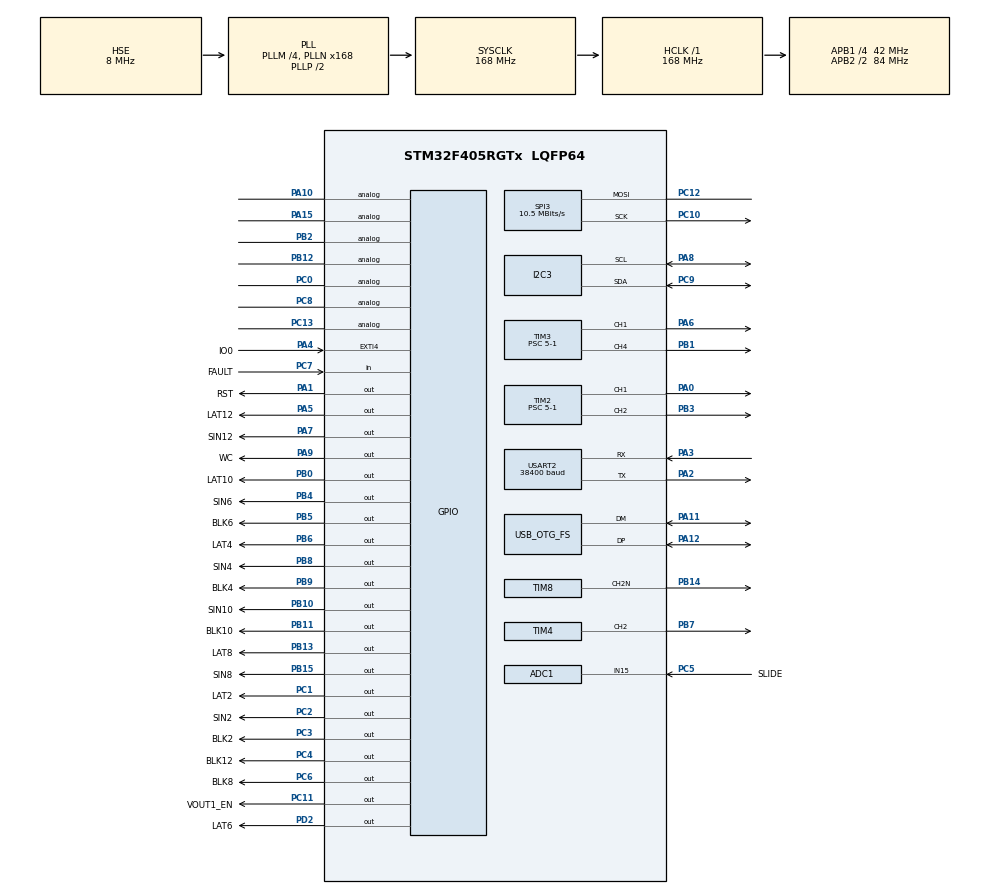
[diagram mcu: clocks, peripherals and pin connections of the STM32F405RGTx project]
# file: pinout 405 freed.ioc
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Dma.SPI3_TX.0.FIFOMode=DMA_FIFOMODE_DISABLE
Dma.SPI3_TX.0.Priority=DMA_PRIORITY_HIGH
FREERTOS.Queues01=myQueue01,2,LEDDataShift_t,0,Dynamic,NULL,NULL
PH0-OSC_IN.Signal=RCC_OSC_IN
SPI3.Direction=SPI_DIRECTION_1LINE
SPI3.VirtualType=VM_MASTER
Dma.USART2_TX.3.MemInc=DMA_MINC_ENABLE
NVIC.DMA1_Stream2_IRQn=true\:5\:0\:false\:false\:true\:true\:false\:true
PC12.Signal=SPI3_MOSI
FREERTOS.Events01=GlobalStatus,Dynamic,NULL
PC6.GPIO_Label=BLK8
VP_RTC_VS_RTC_Activate.Mode=RTC_Enabled
PB6.GPIO_Label=LAT4
PB13.Signal=GPIO_Output
PA5.PinState=GPIO_PIN_RESET
PB3.GPIO_Speed=GPIO_SPEED_FREQ_MEDIUM
TIM3.Channel-PWM\ Generation4\ CH4=TIM_CHANNEL_4
RCC.SYSCLKSource=RCC_SYSCLKSOURCE_PLLCLK
VP_TIM1_VS_no_output1.Mode=PWM Generation1 No Output
VP_TIM2_VS_ClockSourceITR.Mode=TriggerSource_ITR0
TIM8.OCNPolarity_2=TIM_OCNPOLARITY_HIGH
RCC.APB2TimFreq_Value=168000000
PB6.Signal=GPIO_Output
PC7.Signal=GPIO_Input
Dma.ADC1.1.PeriphDataAlignment=DMA_PDATAALIGN_HALFWORD
Dma.USART2_RX.2.Priority=DMA_PRIORITY_HIGH
PC3.Signal=GPIO_Output
PC1.PinState=GPIO_PIN_RESET
Dma.SPI3_TX.0.Direction=DMA_MEMORY_TO_PERIPH
VP_TIM4_VS_ControllerModeTrigger.Mode=Trigger Mode
RCC.RCC_RTC_Clock_Source_FROM_HSE=RCC_RTCCLKSOURCE_HSE_DIV25
PB2.Signal=GPIO_Analog
PC13-ANTI_TAMP.Signal=GPIO_Analog
SH.ADCx_IN15.0=ADC1_IN15,IN15
TIM8.OCMode_PWM-PWM\ Generation2\ CH2N=TIM_OCMODE_PWM1
PC4.GPIO_Label=BLK12
PB1.GPIO_Speed=GPIO_SPEED_FREQ_MEDIUM
PB14.Mode=PWM Generation2 CH2N
RTC.AlarmSubSecondMask=RTC_ALARMSUBSECONDMASK_ALL
PC9.Mode=I2C
SH.S_TIM4_CH2.0=TIM4_CH2,PWM Generation2 CH2
PA8.Signal=I2C3_SCL
TIM4.Period=84-1
VP_TIM1_VS_ClockSourceINT.Mode=Internal
ADC1.SamplingTime-0\#ChannelRegularConversion=ADC_SAMPLETIME_3CYCLES
Mcu.Package=LQFP64
PB9.Signal=GPIO_Output
TIM2.Prescaler=5-1
PB1.Signal=S_TIM3_CH4
NVIC.TimeBase=TIM7_IRQn
SPI3.Mode=SPI_MODE_MASTER
NVIC.TimeBaseIP=TIM7
PA10.Signal=GPIO_Analog
VP_RTC_VS_RTC_Calendar.Mode=RTC_Calendar
Dma.USART2_RX.2.Direction=DMA_PERIPH_TO_MEMORY
TIM2.Pulse-PWM\ Generation2\ CH2=75
RCC.APB2CLKDivider=RCC_HCLK_DIV2
RCC.APB1TimFreq_Value=84000000
TIM1.Period=168-1
PA6.GPIO_Speed=GPIO_SPEED_FREQ_MEDIUM
TIM4.OC2Preload_PWM=DISABLE
NVIC.DMA1_Stream6_IRQn=true\:5\:0\:false\:false\:true\:true\:false\:true
PA4.GPIO_Label=IO0
TIM4.Pulse-PWM\ Generation2\ CH2=75
NVIC.RCC_IRQn=true\:5\:0\:false\:false\:true\:true\:true\:false
NVIC.EXTI4_IRQn=true\:5\:0\:false\:false\:true\:true\:true\:true
NVIC.HASH_RNG_IRQn=true\:5\:0\:false\:false\:true\:true\:true\:true
Dma.I2C3_TX.5.Instance=DMA1_Stream4
FREERTOS.Tasks01=TimerAndLatch,48,128,startTimerAndLatch,Default,NULL,Dynamic,NULL,NULL;LEDShifter,25,128,StartLEDShift,Default,NULL,Dynamic,NULL,NULL;RGBShift,26,512,StartRGBShift,Default,NULL,Dynamic,NULL,NULL;RTCManage,24,256,StartRTCManage,Default,NULL,Dynamic,NULL,NULL;ClockManage,48,512,StartClockMngr,Default,NULL,Dynamic,NULL,NULL
ADC1.Rank-0\#ChannelRegularConversion=1
Dma.I2C3_RX.4.Mode=DMA_NORMAL
PC4.PinState=GPIO_PIN_SET
TIM3.AutoReloadPreload=TIM_AUTORELOAD_PRELOAD_DISABLE
VP_TIM3_VS_ControllerModeTrigger.Mode=Trigger Mode
PA9.GPIO_Label=WC
PC6.Signal=GPIO_Output
PC2.Signal=GPIO_Output
PB11.GPIO_Label=BLK10
VP_TIM8_VS_ClockSourceITR.Mode=TriggerSource_ITR0
Dma.USART2_TX.3.PeriphInc=DMA_PINC_DISABLE
TIM4.TIM_MasterSlaveMode=TIM_MASTERSLAVEMODE_ENABLE
TIM8.TIM_MasterSlaveMode=TIM_MASTERSLAVEMODE_ENABLE
PC0.Signal=GPIO_Analog
RCC.APB1CLKDivider=RCC_HCLK_DIV4
PC14-OSC32_IN.Signal=RCC_OSC32_IN
TIM2.OCPolarity_2=TIM_OCPOLARITY_HIGH
USART2.BaudRate=38400
Dma.USART2_RX.2.Mode=DMA_CIRCULAR
PA0-WKUP.Signal=S_TIM2_CH1_ETR
PA3.Mode=Asynchronous
TIM1.AutoReloadPreload=TIM_AUTORELOAD_PRELOAD_DISABLE
PB8.GPIO_Label=SIN4
TIM3.Pulse-PWM\ Generation1\ CH1=75
Dma.I2C3_RX.4.MemInc=DMA_MINC_ENABLE
RTC.AlarmMaskMinutes=RTC_ALARMMASK_MINUTES
PB14.GPIO_Speed=GPIO_SPEED_FREQ_MEDIUM
Dma.I2C3_RX.4.MemDataAlignment=DMA_MDATAALIGN_BYTE
RTC.Year=21
Dma.I2C3_TX.5.FIFOMode=DMA_FIFOMODE_DISABLE
PA9.Signal=GPIO_Output
PA4.GPIO_ModeDefaultEXTI=GPIO_MODE_IT_RISING_FALLING
VP_TIM8_VS_ClockSourceINT.Mode=Internal
RTC.Format=RTC_FORMAT_BIN
Dma.SPI3_TX.0.PeriphInc=DMA_PINC_DISABLE
Dma.I2C3_TX.5.MemDataAlignment=DMA_MDATAALIGN_BYTE
PB10.Signal=GPIO_Output
PC6.PinState=GPIO_PIN_SET
PB14.Signal=TIM8_CH2N
PA5.Signal=GPIO_Output
PC12.Mode=Simplex_Bidirectional_Master
TIM1.TIM_MasterOutputTrigger=TIM_TRGO_OC1REF
PB13.PinState=GPIO_PIN_RESET
PB4.GPIO_Label=SIN6
PB15.GPIO_Label=SIN8
VP_TIM4_VS_ClockSourceITR.Mode=TriggerSource_ITR0
Dma.USART2_TX.3.Mode=DMA_NORMAL
PA1.GPIO_Label=RST
TIM3.OC4Preload_PWM=DISABLE
Dma.I2C3_TX.5.PeriphInc=DMA_PINC_DISABLE
RCC.RCC_RTC_Clock_SourceVirtual=RCC_RTCCLKSOURCE_HSE_DIV31
Dma.SPI3_TX.0.Instance=DMA1_Stream7
TIM2.Period=84-1
PA13.Mode=Serial_Wire
NVIC.RTC_Alarm_IRQn=true\:5\:0\:false\:false\:true\:true\:true\:true
NVIC.TIM1_BRK_TIM9_IRQn=true\:5\:0\:false\:false\:true\:true\:true\:true
NVIC.TIM1_CC_IRQn=true\:5\:0\:false\:false\:true\:true\:true\:true
TIM8.Period=84-1
PC7.GPIO_Label=FAULT
PA4.Signal=GPXTI4
PB5.Signal=GPIO_Output
ADC1.master=1
PA5.GPIO_Label=LAT12
Dma.SPI3_TX.0.Mode=DMA_NORMAL
PB6.PinState=GPIO_PIN_RESET
PB9.PinState=GPIO_PIN_SET
PA11.Signal=USB_OTG_FS_DM
SH.S_TIM2_CH1_ETR.0=TIM2_CH1,PWM Generation1 CH1
RTC.HourFormat=RTC_HOURFORMAT_12
ProjectManager.HeapSize=0x1000
Dma.I2C3_RX.4.Instance=DMA1_Stream2
Dma.USART2_TX.3.Priority=DMA_PRIORITY_HIGH
VP_TIM4_VS_ClockSourceINT.Mode=Internal
NVIC.PriorityGroup=NVIC_PRIORITYGROUP_4
TIM2.TIM_MasterSlaveMode=TIM_MASTERSLAVEMODE_ENABLE
TIM2.AutoReloadPreload=TIM_AUTORELOAD_PRELOAD_DISABLE
PC3.GPIO_Label=BLK2
PA8.Mode=I2C
PD2.Signal=GPIO_Output
RTC.Seconds=45
PB0.Signal=GPIO_Output
Dma.I2C3_RX.4.FIFOMode=DMA_FIFOMODE_DISABLE
RTC.Date=11
Dma.I2C3_TX.5.Mode=DMA_NORMAL
PC1.Signal=GPIO_Output
PD2.GPIO_Label=LAT6
Mcu.Family=STM32F4
Dma.USART2_RX.2.PeriphDataAlignment=DMA_PDATAALIGN_BYTE
Dma.SPI3_TX.0.MemInc=DMA_MINC_ENABLE
VP_TIM2_VS_OPM.Mode=OPM_bit
USB_DEVICE.CLASS_NAME_FS=CDC
VP_TIM1_VS_OPM.Mode=OPM_bit
RCC.CortexFreq_Value=168000000
Dma.ADC1.1.MemDataAlignment=DMA_MDATAALIGN_HALFWORD
RTC.Alarm=RTC_ALARM_A
TIM1.RepetitionCounter=16-1
VP_TIM3_VS_OPM.Mode=OPM_bit
VP_TIM4_VS_OPM.Mode=OPM_bit
PC10.Signal=SPI3_SCK
PA11.Mode=Device_Only
VP_TIM8_VS_ControllerModeTrigger.Mode=Trigger Mode
PB0.GPIO_Label=LAT10
VP_TIM8_VS_OPM.Mode=OPM_bit
USB_DEVICE.VirtualMode-CDC_FS=Cdc
Dma.USART2_TX.3.Direction=DMA_MEMORY_TO_PERIPH
Dma.SPI3_TX.0.PeriphDataAlignment=DMA_PDATAALIGN_BYTE
TIM2.Channel-PWM\ Generation2\ CH2=TIM_CHANNEL_2
PB13.GPIO_Label=LAT8
PB11.Signal=GPIO_Output
NVIC.DMA1_Stream4_IRQn=true\:5\:0\:false\:false\:true\:true\:false\:true
PB15.Signal=GPIO_Output
VP_RTC_VS_RTC_Alarm_A_Intern.Mode=Alarm A
ProjectManager.StackSize=0x1000
PC3.PinState=GPIO_PIN_SET
VP_FREERTOS_VS_CMSIS_V2.Mode=CMSIS_V2
PA12.Signal=USB_OTG_FS_DP
TIM1.Prescaler=20-1
PB0.PinState=GPIO_PIN_RESET
RCC.RCC_RTC_Clock_Source=RCC_RTCCLKSOURCE_LSE
Dma.ADC1.1.Instance=DMA2_Stream0
RCC.HCLKFreq_Value=168000000
Dma.I2C3_RX.4.Priority=DMA_PRIORITY_LOW
TIM3.Period=84-1
TIM3.OC1Preload_PWM=DISABLE
PB5.PinState=GPIO_PIN_SET
Dma.USART2_RX.2.MemDataAlignment=DMA_MDATAALIGN_BYTE
NVIC.DMA2_Stream0_IRQn=true\:5\:0\:false\:false\:true\:true\:false\:true
RCC.AHBFreq_Value=168000000
PH0-OSC_IN.Mode=HSE-External-Clock-Source
SPI3.DataSize=SPI_DATASIZE_8BIT
TIM3.Channel-PWM\ Generation1\ CH1=TIM_CHANNEL_1
ADC1.Channel-0\#ChannelRegularConversion=ADC_CHANNEL_15
RCC.HSE_VALUE=8000000
RTC.Minutes=10
PA0-WKUP.GPIO_Speed=GPIO_SPEED_FREQ_MEDIUM
Dma.I2C3_TX.5.MemInc=DMA_MINC_ENABLE
RTC.Month=RTC_MONTH_MAY
PC14-OSC32_IN.Mode=LSE-External-Clock-Source
PA14.Mode=Serial_Wire
TIM3.Prescaler=5-1
PC11.GPIO_Label=VOUT1_EN
Dma.ADC1.1.Priority=DMA_PRIORITY_LOW
TIM8.Pulse-PWM\ Generation2\ CH2N=70
PB7.Signal=S_TIM4_CH2
Dma.ADC1.1.Mode=DMA_CIRCULAR
TIM2.Channel-PWM\ Generation1\ CH1=TIM_CHANNEL_1
SH.S_TIM3_CH1.0=TIM3_CH1,PWM Generation1 CH1
VP_TIM3_VS_ClockSourceITR.Mode=TriggerSource_ITR0
TIM8.OC2Preload_PWM=DISABLE
TIM3.OCPolarity_4=TIM_OCPOLARITY_HIGH
Dma.SPI3_TX.0.MemDataAlignment=DMA_MDATAALIGN_BYTE
NVIC.DMA1_Stream7_IRQn=true\:5\:0\:false\:false\:true\:true\:false\:true
TIM3.OCPolarity_1=TIM_OCPOLARITY_HIGH
PH1-OSC_OUT.Mode=HSE-External-Clock-Source
PA6.Signal=S_TIM3_CH1
USART2.VirtualMode=VM_ASYNC
Dma.ADC1.1.Direction=DMA_PERIPH_TO_MEMORY
Dma.I2C3_TX.5.Direction=DMA_MEMORY_TO_PERIPH
NVIC.OTG_FS_IRQn=true\:5\:0\:false\:false\:true\:true\:false\:true
Dma.ADC1.1.MemInc=DMA_MINC_ENABLE
TIM8.Channel-PWM\ Generation2\ CH2N=TIM_CHANNEL_2
USB_OTG_FS.VirtualMode=Device_Only
PA15.Signal=GPIO_Analog
PB11.PinState=GPIO_PIN_SET
TIM8.Prescaler=10-1
PB5.GPIO_Label=BLK6
Dma.Request2=USART2_RX
Dma.Request1=ADC1
Dma.Request4=I2C3_RX
Dma.Request3=USART2_TX
Dma.Request5=I2C3_TX
PC5.Signal=ADCx_IN15
Dma.Request0=SPI3_TX
PC2.GPIO_Label=SIN2
NVIC.TIM7_IRQn=true\:0\:0\:false\:false\:true\:false\:false\:true
VP_TIM3_VS_ClockSourceINT.Mode=Internal
TIM2.OC1Preload_PWM=DISABLE
PB4.Signal=GPIO_Output
PA3.Signal=USART2_RX
PB7.GPIO_Speed=GPIO_SPEED_FREQ_MEDIUM
PC15-OSC32_OUT.Mode=LSE-External-Clock-Source
Dma.USART2_TX.3.MemDataAlignment=DMA_MDATAALIGN_BYTE
PB9.GPIO_Label=BLK4
Dma.USART2_TX.3.Instance=DMA1_Stream6
USB_DEVICE.VirtualModeFS=Cdc_FS
PC4.GPIO_PuPd=GPIO_NOPULL
TIM3.OCMode_PWM-PWM\ Generation4\ CH4=TIM_OCMODE_PWM1
VP_SYS_VS_tim7.Mode=TIM7
PC11.Signal=GPIO_Output
RTC.AlarmMaskDateWeekDay=RTC_ALARMMASK_DATEWEEKDAY
PC8.Signal=GPIO_Analog
PC4.Signal=GPIO_Output
PC10.Mode=Simplex_Bidirectional_Master
TIM1.Pulse-PWM\ Generation1\ No\ Output=150
Dma.I2C3_RX.4.PeriphInc=DMA_PINC_DISABLE
VP_RNG_VS_RNG.Mode=RNG_Activate
TIM2.Pulse-PWM\ Generation1\ CH1=75
TIM1.Channel-PWM\ Generation1\ No\ Output=TIM_CHANNEL_1
PA13.Signal=SYS_JTMS-SWDIO
SH.S_TIM2_CH2.0=TIM2_CH2,PWM Generation2 CH2
NVIC.TIM8_CC_IRQn=true\:5\:0\:false\:false\:true\:true\:true\:true
Dma.USART2_RX.2.MemInc=DMA_MINC_ENABLE
Dma.I2C3_TX.5.PeriphDataAlignment=DMA_PDATAALIGN_BYTE
RTC.TimeFormat=RTC_HOURFORMAT12_AM
ProjectManager.TargetToolchain=STM32CubeIDE
PB10.GPIO_Label=SIN10
NVIC.DMA1_Stream5_IRQn=true\:5\:0\:false\:false\:true\:true\:false\:true
VP_USB_DEVICE_VS_USB_DEVICE_CDC_FS.Mode=CDC_FS
Dma.USART2_TX.3.PeriphDataAlignment=DMA_PDATAALIGN_BYTE
TIM4.Prescaler=5-1
RCC.LSE_VALUE=32768
PC15-OSC32_OUT.Signal=RCC_OSC32_OUT
PA1.Signal=GPIO_Output
Dma.USART2_TX.3.FIFOMode=DMA_FIFOMODE_DISABLE
PD2.PinState=GPIO_PIN_RESET
board=custom
RCC.VCOOutputFreq_Value=336000000
Dma.ADC1.1.FIFOMode=DMA_FIFOMODE_DISABLE
Dma.USART2_RX.2.PeriphInc=DMA_PINC_DISABLE
TIM4.Channel-PWM\ Generation2\ CH2=TIM_CHANNEL_2
RCC.APB2Freq_Value=84000000
SPI3.CalculateBaudRate=10.5 MBits/s
TIM2.OCMode_PWM-PWM\ Generation2\ CH2=TIM_OCMODE_PWM1
VP_TIM2_VS_ClockSourceINT.Mode=Internal
SPI3.BaudRatePrescaler=SPI_BAUDRATEPRESCALER_4
PC1.GPIO_Label=LAT2
PH1-OSC_OUT.Signal=RCC_OSC_OUT
Dma.ADC1.1.PeriphInc=DMA_PINC_DISABLE
Dma.I2C3_RX.4.Direction=DMA_PERIPH_TO_MEMORY
Mcu.Name=STM32F405RGTx
Dma.I2C3_TX.5.Priority=DMA_PRIORITY_LOW
PA2.Signal=USART2_TX
RTC.AlarmMaskHours=RTC_ALARMMASK_HOURS
Dma.I2C3_RX.4.PeriphDataAlignment=DMA_PDATAALIGN_BYTE
RCC.48MHZClocksFreq_Value=48000000
PB3.Signal=S_TIM2_CH2
RCC.SYSCLKFreq_VALUE=168000000
RTC.Hours=12
PA7.GPIO_Label=SIN12
PC2.PinState=GPIO_PIN_RESET
PA12.Mode=Device_Only
VP_TIM2_VS_ControllerModeTrigger.Mode=Trigger Mode
TIM2.OC2Preload_PWM=DISABLE
PC5.GPIO_Label=SLIDE
Dma.USART2_RX.2.Instance=DMA1_Stream5
TIM3.TIM_MasterSlaveMode=TIM_MASTERSLAVEMODE_ENABLE
PA14.Signal=SYS_JTCK-SWCLK
RCC.HSI_VALUE=16000000
RCC.PLLQ=7
ADC1.NbrOfConversionFlag=1
RCC.PLLM=4
RCC.PLLN=168
PA2.Mode=Asynchronous
PB8.Signal=GPIO_Output
Dma.USART2_RX.2.FIFOMode=DMA_FIFOMODE_DISABLE
PC9.Signal=I2C3_SDA
TIM4.OCMode_PWM-PWM\ Generation2\ CH2=TIM_OCMODE_PWM1
RCC.APB1Freq_Value=42000000
TIM3.Pulse-PWM\ Generation4\ CH4=75
PB12.Signal=GPIO_Analog
TIM1.TIM_MasterSlaveMode=TIM_MASTERSLAVEMODE_DISABLE
PC3.GPIO_PuPd=GPIO_NOPULL
SH.S_TIM3_CH4.0=TIM3_CH4,PWM Generation4 CH4
PA7.Signal=GPIO_Output

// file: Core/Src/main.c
/* USER CODE BEGIN Header */
/**
  ******************************************************************************
  * @file           : main.c
  * @brief          : Main program body
  ******************************************************************************
  * @attention
  *
  * <h2><center>&copy; Copyright (c) 2021 STMicroelectronics.
  * All rights reserved.</center></h2>
  *
  * This software component is licensed by ST under Ultimate Liberty license
  * SLA0044, the "License"; You may not use this file except in compliance with
  * the License. You may obtain a copy of the License at:
  *                             www.st.com/SLA0044
  *
  ******************************************************************************
  */
/* USER CODE END Header */
#include "main.h"
#include "cmsis_os.h"
#include "usb_device.h"

/* USER CODE BEGIN Includes */
//#include "time.h"
#include "cheapLibation.h"
#include "ColorDefinitions.h"
#include "mytime.h"
#include "usbd_cdc_if.h"

/* USER CODE END Includes */

/* USER CODE BEGIN PTD */
typedef struct {
	uint8_t flags;
	uint8_t mincnt;
	uint8_t hrcnt;
	uint8_t time;
}LEDDataShift_t;

/* USER CODE END PTD */

/* USER CODE BEGIN PD */
#define NUMLED 60
#define GLOBAL 0
#define R_LED 3
#define B_LED 1
#define G_LED 2
#define MINMASK 0x00000001U
#define HRMASK	0x00000002U
#define LATMASK	0x00000008U
#define TIMMASK	0x00000004U
#define WIFISTATUS 0x000080U
#define WIFISTATUSD 0x000100U
#define ESPDATA 0x000040U
#define SETTIME 0x000020U

/* USER CODE END PD */

ADC_HandleTypeDef hadc1;
DMA_HandleTypeDef hdma_adc1;

I2C_HandleTypeDef hi2c3;
DMA_HandleTypeDef hdma_i2c3_rx;
DMA_HandleTypeDef hdma_i2c3_tx;

RNG_HandleTypeDef hrng;

RTC_HandleTypeDef hrtc;

SPI_HandleTypeDef hspi3;
DMA_HandleTypeDef hdma_spi3_tx;

TIM_HandleTypeDef htim1;
TIM_HandleTypeDef htim2;
TIM_HandleTypeDef htim3;
TIM_HandleTypeDef htim4;
TIM_HandleTypeDef htim8;

UART_HandleTypeDef huart2;
DMA_HandleTypeDef hdma_usart2_rx;
DMA_HandleTypeDef hdma_usart2_tx;

/* Definitions for TimerAndLatch */
osThreadId_t TimerAndLatchHandle;
const osThreadAttr_t TimerAndLatch_attributes = {
  .name = "TimerAndLatch",
  .stack_size = 128 * 4,
  .priority = (osPriority_t) osPriorityRealtime,
};
/* Definitions for LEDShifter */
osThreadId_t LEDShifterHandle;
const osThreadAttr_t LEDShifter_attributes = {
  .name = "LEDShifter",
  .stack_size = 128 * 4,
  .priority = (osPriority_t) osPriorityNormal1,
};
/* Definitions for RGBShift */
osThreadId_t RGBShiftHandle;
const osThreadAttr_t RGBShift_attributes = {
  .name = "RGBShift",
  .stack_size = 512 * 4,
  .priority = (osPriority_t) osPriorityNormal2,
};
/* Definitions for RTCManage */
osThreadId_t RTCManageHandle;
const osThreadAttr_t RTCManage_attributes = {
  .name = "RTCManage",
  .stack_size = 256 * 4,
  .priority = (osPriority_t) osPriorityNormal,
};
/* Definitions for ClockManage */
osThreadId_t ClockManageHandle;
const osThreadAttr_t ClockManage_attributes = {
  .name = "ClockManage",
  .stack_size = 512 * 4,
  .priority = (osPriority_t) osPriorityRealtime,
};
/* Definitions for myQueue01 */
osMessageQueueId_t myQueue01Handle;
const osMessageQueueAttr_t myQueue01_attributes = {
  .name = "myQueue01"
};
/* Definitions for GlobalStatus */
osEventFlagsId_t GlobalStatusHandle;
const osEventFlagsAttr_t GlobalStatus_attributes = {
  .name = "GlobalStatus"
};
/* USER CODE BEGIN PV */
uint32_t data[] = {0x70007000, 0x00, 0x08080000};
uint16_t newarr[6];
//DMA_HandleTypeDef hdma_memtomem_dma1_channel1;

uint8_t rxbuff[] = {0x00, 0x00, 0x00, 0x00, 0x00, 0x00, 0x00, 0x00 };
uint8_t txbuff[] = {0x55, 0x00, 0x00, 0x00, 0x00, 0x00, 0x00, 0x00 , 0x00, 0x00 };
uint8_t wififlag = 0;
uint8_t hrs = 0x00;
uint8_t min = 0x00;
/* USER CODE END PV */

void SystemClock_Config(void);
static void MX_GPIO_Init(void);
static void MX_DMA_Init(void);
static void MX_TIM3_Init(void);
static void MX_TIM2_Init(void);
static void MX_TIM1_Init(void);
static void MX_TIM8_Init(void);
static void MX_TIM4_Init(void);
static void MX_SPI3_Init(void);
static void MX_ADC1_Init(void);
static void MX_I2C3_Init(void);
static void MX_USART2_UART_Init(void);
static void MX_RTC_Init(void);
static void MX_RNG_Init(void);
void startTimerAndLatch(void *argument);
void StartLEDShift(void *argument);
void StartRGBShift(void *argument);
void StartRTCManage(void *argument);
void StartClockMngr(void *argument);

/* USER CODE BEGIN PFP */

void HAL_TIM_PWM_PulseFinishedCallback(TIM_HandleTypeDef *htim);
void HAL_GPIO_EXTI_Callback(uint16_t GPIO_Pin);
void HAL_RTC_AlarmAEventCallback(RTC_HandleTypeDef *hrtc);

/* USER CODE END PFP */

int main(void)
{

  /* MCU Configuration--------------------------------------------------------*/

  /* Reset of all peripherals, Initializes the Flash interface and the Systick. */
  HAL_Init();

  /* Configure the system clock */
  SystemClock_Config();

  /* Initialize all configured peripherals */
  MX_GPIO_Init();
  MX_DMA_Init();
  MX_TIM3_Init();
  MX_TIM2_Init();
  MX_TIM1_Init();
  MX_TIM8_Init();
  MX_TIM4_Init();
  MX_SPI3_Init();
  MX_ADC1_Init();
  MX_I2C3_Init();
  MX_USART2_UART_Init();
  MX_RTC_Init();
  MX_RNG_Init();
  /* USER CODE BEGIN 2 */

  // reset wifi to programming mode
//  HAL_GPIO_WritePin(IO0_GPIO_Port, IO0_Pin, GPIO_PIN_SET);
  HAL_GPIO_WritePin(RST_GPIO_Port, RST_Pin, GPIO_PIN_RESET);
//  HAL_Delay(500);
//  HAL_GPIO_WritePin(RST_GPIO_Port, RST_Pin, GPIO_PIN_SET);

  // enable all the slave timers
  HAL_TIM_PWM_Start(&htim2, TIM_CHANNEL_2);
  HAL_TIM_PWM_Start(&htim2, TIM_CHANNEL_1);
  HAL_TIM_PWM_Start(&htim3, TIM_CHANNEL_1);
  HAL_TIM_PWM_Start(&htim3, TIM_CHANNEL_4);
  HAL_TIM_PWM_Start(&htim4, TIM_CHANNEL_2);
  HAL_TIMEx_PWMN_Start(&htim8, TIM_CHANNEL_2);
//  uint8_t sttest = beatsin8()

//  time_t now;
//  localtime_r(&now);
//  setenv("TZ")

  /* USER CODE END 2 */

  /* Init scheduler */
  osKernelInitialize();

  /* Create the queue(s) */
  /* creation of myQueue01 */
  myQueue01Handle = osMessageQueueNew (2, sizeof(LEDDataShift_t), &myQueue01_attributes);

  /* Create the thread(s) */
  /* creation of TimerAndLatch */
  TimerAndLatchHandle = osThreadNew(startTimerAndLatch, NULL, &TimerAndLatch_attributes);

  /* creation of LEDShifter */
  LEDShifterHandle = osThreadNew(StartLEDShift, NULL, &LEDShifter_attributes);

  /* creation of RGBShift */
  RGBShiftHandle = osThreadNew(StartRGBShift, NULL, &RGBShift_attributes);

  /* creation of RTCManage */
  RTCManageHandle = osThreadNew(StartRTCManage, NULL, &RTCManage_attributes);

  /* creation of ClockManage */
  ClockManageHandle = osThreadNew(StartClockMngr, NULL, &ClockManage_attributes);

  /* Create the event(s) */
  /* creation of GlobalStatus */
  GlobalStatusHandle = osEventFlagsNew(&GlobalStatus_attributes);

  /* Start scheduler */
  osKernelStart();

  /* We should never get here as control is now taken by the scheduler */
  /* Infinite loop */
  while (1)
  {

  }
}

void SystemClock_Config(void)
{
  RCC_OscInitTypeDef RCC_OscInitStruct = {0};
  RCC_ClkInitTypeDef RCC_ClkInitStruct = {0};
  RCC_PeriphCLKInitTypeDef PeriphClkInitStruct = {0};

  /** Configure the main internal regulator output voltage
  */
  __HAL_RCC_PWR_CLK_ENABLE();
  __HAL_PWR_VOLTAGESCALING_CONFIG(PWR_REGULATOR_VOLTAGE_SCALE1);
  /** Initializes the RCC Oscillators according to the specified parameters
  * in the RCC_OscInitTypeDef structure.
  */
  RCC_OscInitStruct.OscillatorType = RCC_OSCILLATORTYPE_HSE|RCC_OSCILLATORTYPE_LSE;
  RCC_OscInitStruct.HSEState = RCC_HSE_BYPASS;
  RCC_OscInitStruct.LSEState = RCC_LSE_BYPASS;
  RCC_OscInitStruct.PLL.PLLState = RCC_PLL_ON;
  RCC_OscInitStruct.PLL.PLLSource = RCC_PLLSOURCE_HSE;
  RCC_OscInitStruct.PLL.PLLM = 4;
  RCC_OscInitStruct.PLL.PLLN = 168;
  RCC_OscInitStruct.PLL.PLLP = RCC_PLLP_DIV2;
  RCC_OscInitStruct.PLL.PLLQ = 7;
  if (HAL_RCC_OscConfig(&RCC_OscInitStruct) != HAL_OK)
  {
    Error_Handler();
  }
  /** Initializes the CPU, AHB and APB buses clocks
  */
  RCC_ClkInitStruct.ClockType = RCC_CLOCKTYPE_HCLK|RCC_CLOCKTYPE_SYSCLK
                              |RCC_CLOCKTYPE_PCLK1|RCC_CLOCKTYPE_PCLK2;
  RCC_ClkInitStruct.SYSCLKSource = RCC_SYSCLKSOURCE_PLLCLK;
  RCC_ClkInitStruct.AHBCLKDivider = RCC_SYSCLK_DIV1;
  RCC_ClkInitStruct.APB1CLKDivider = RCC_HCLK_DIV4;
  RCC_ClkInitStruct.APB2CLKDivider = RCC_HCLK_DIV2;

  if (HAL_RCC_ClockConfig(&RCC_ClkInitStruct, FLASH_LATENCY_5) != HAL_OK)
  {
    Error_Handler();
  }
  PeriphClkInitStruct.PeriphClockSelection = RCC_PERIPHCLK_RTC;
  PeriphClkInitStruct.RTCClockSelection = RCC_RTCCLKSOURCE_LSE;
  if (HAL_RCCEx_PeriphCLKConfig(&PeriphClkInitStruct) != HAL_OK)
  {
    Error_Handler();
  }
}

static void MX_ADC1_Init(void)
{

  ADC_ChannelConfTypeDef sConfig = {0};

  /** Configure the global features of the ADC (Clock, Resolution, Data Alignment and number of conversion)
  */
  hadc1.Instance = ADC1;
  hadc1.Init.ClockPrescaler = ADC_CLOCK_SYNC_PCLK_DIV4;
  hadc1.Init.Resolution = ADC_RESOLUTION_12B;
  hadc1.Init.ScanConvMode = DISABLE;
  hadc1.Init.ContinuousConvMode = DISABLE;
  hadc1.Init.DiscontinuousConvMode = DISABLE;
  hadc1.Init.ExternalTrigConvEdge = ADC_EXTERNALTRIGCONVEDGE_NONE;
  hadc1.Init.ExternalTrigConv = ADC_SOFTWARE_START;
  hadc1.Init.DataAlign = ADC_DATAALIGN_RIGHT;
  hadc1.Init.NbrOfConversion = 1;
  hadc1.Init.DMAContinuousRequests = DISABLE;
  hadc1.Init.EOCSelection = ADC_EOC_SINGLE_CONV;
  if (HAL_ADC_Init(&hadc1) != HAL_OK)
  {
    Error_Handler();
  }
  /** Configure for the selected ADC regular channel its corresponding rank in the sequencer and its sample time.
  */
  sConfig.Channel = ADC_CHANNEL_15;
  sConfig.Rank = 1;
  sConfig.SamplingTime = ADC_SAMPLETIME_3CYCLES;
  if (HAL_ADC_ConfigChannel(&hadc1, &sConfig) != HAL_OK)
  {
    Error_Handler();
  }

}

static void MX_I2C3_Init(void)
{

  hi2c3.Instance = I2C3;
  hi2c3.Init.ClockSpeed = 100000;
  hi2c3.Init.DutyCycle = I2C_DUTYCYCLE_2;
  hi2c3.Init.OwnAddress1 = 0;
  hi2c3.Init.AddressingMode = I2C_ADDRESSINGMODE_7BIT;
  hi2c3.Init.DualAddressMode = I2C_DUALADDRESS_DISABLE;
  hi2c3.Init.OwnAddress2 = 0;
  hi2c3.Init.GeneralCallMode = I2C_GENERALCALL_DISABLE;
  hi2c3.Init.NoStretchMode = I2C_NOSTRETCH_DISABLE;
  if (HAL_I2C_Init(&hi2c3) != HAL_OK)
  {
    Error_Handler();
  }

}

static void MX_RNG_Init(void)
{

  hrng.Instance = RNG;
  if (HAL_RNG_Init(&hrng) != HAL_OK)
  {
    Error_Handler();
  }

}

static void MX_RTC_Init(void)
{

  RTC_TimeTypeDef sTime = {0};
  RTC_DateTypeDef sDate = {0};
  RTC_AlarmTypeDef sAlarm = {0};

  /** Initialize RTC Only
  */
  hrtc.Instance = RTC;
  hrtc.Init.HourFormat = RTC_HOURFORMAT_12;
  hrtc.Init.AsynchPrediv = 127;
  hrtc.Init.SynchPrediv = 255;
  hrtc.Init.OutPut = RTC_OUTPUT_DISABLE;
  hrtc.Init.OutPutPolarity = RTC_OUTPUT_POLARITY_HIGH;
  hrtc.Init.OutPutType = RTC_OUTPUT_TYPE_OPENDRAIN;
  if (HAL_RTC_Init(&hrtc) != HAL_OK)
  {
    Error_Handler();
  }

  /** Initialize RTC and set the Time and Date
  */
  sTime.Hours = 12;
  sTime.Minutes = 10;
  sTime.Seconds = 45;
  sTime.TimeFormat = RTC_HOURFORMAT12_AM;
  sTime.DayLightSaving = RTC_DAYLIGHTSAVING_NONE;
  sTime.StoreOperation = RTC_STOREOPERATION_RESET;
  if (HAL_RTC_SetTime(&hrtc, &sTime, RTC_FORMAT_BIN) != HAL_OK)
  {
    Error_Handler();
  }
  sDate.WeekDay = RTC_WEEKDAY_MONDAY;
  sDate.Month = RTC_MONTH_MAY;
  sDate.Date = 11;
  sDate.Year = 21;

  if (HAL_RTC_SetDate(&hrtc, &sDate, RTC_FORMAT_BIN) != HAL_OK)
  {
    Error_Handler();
  }
  /** Enable the Alarm A
  */
  sAlarm.AlarmTime.Hours = 1;
  sAlarm.AlarmTime.Minutes = 0;
  sAlarm.AlarmTime.Seconds = 0;
  sAlarm.AlarmTime.SubSeconds = 0;
  sAlarm.AlarmTime.TimeFormat = RTC_HOURFORMAT12_AM;
  sAlarm.AlarmTime.DayLightSaving = RTC_DAYLIGHTSAVING_NONE;
  sAlarm.AlarmTime.StoreOperation = RTC_STOREOPERATION_RESET;
  sAlarm.AlarmMask = RTC_ALARMMASK_DATEWEEKDAY|RTC_ALARMMASK_HOURS
                              |RTC_ALARMMASK_MINUTES;
  sAlarm.AlarmSubSecondMask = RTC_ALARMSUBSECONDMASK_ALL;
  sAlarm.AlarmDateWeekDaySel = RTC_ALARMDATEWEEKDAYSEL_DATE;
  sAlarm.AlarmDateWeekDay = 1;
  sAlarm.Alarm = RTC_ALARM_A;
  if (HAL_RTC_SetAlarm_IT(&hrtc, &sAlarm, RTC_FORMAT_BIN) != HAL_OK)
  {
    Error_Handler();
  }

}

static void MX_SPI3_Init(void)
{

  /* SPI3 parameter configuration*/
  hspi3.Instance = SPI3;
  hspi3.Init.Mode = SPI_MODE_MASTER;
  hspi3.Init.Direction = SPI_DIRECTION_1LINE;
  hspi3.Init.DataSize = SPI_DATASIZE_8BIT;
  hspi3.Init.CLKPolarity = SPI_POLARITY_LOW;
  hspi3.Init.CLKPhase = SPI_PHASE_1EDGE;
  hspi3.Init.NSS = SPI_NSS_SOFT;
  hspi3.Init.BaudRatePrescaler = SPI_BAUDRATEPRESCALER_4;
  hspi3.Init.FirstBit = SPI_FIRSTBIT_MSB;
  hspi3.Init.TIMode = SPI_TIMODE_DISABLE;
  hspi3.Init.CRCCalculation = SPI_CRCCALCULATION_DISABLE;
  hspi3.Init.CRCPolynomial = 10;
  if (HAL_SPI_Init(&hspi3) != HAL_OK)
  {
    Error_Handler();
  }

}

static void MX_TIM1_Init(void)
{

  TIM_ClockConfigTypeDef sClockSourceConfig = {0};
  TIM_MasterConfigTypeDef sMasterConfig = {0};
  TIM_OC_InitTypeDef sConfigOC = {0};
  TIM_BreakDeadTimeConfigTypeDef sBreakDeadTimeConfig = {0};

  htim1.Instance = TIM1;
  htim1.Init.Prescaler = 20-1;
  htim1.Init.CounterMode = TIM_COUNTERMODE_UP;
  htim1.Init.Period = 168-1;
  htim1.Init.ClockDivision = TIM_CLOCKDIVISION_DIV1;
  htim1.Init.RepetitionCounter = 16-1;
  htim1.Init.AutoReloadPreload = TIM_AUTORELOAD_PRELOAD_DISABLE;
  if (HAL_TIM_Base_Init(&htim1) != HAL_OK)
  {
    Error_Handler();
  }
  sClockSourceConfig.ClockSource = TIM_CLOCKSOURCE_INTERNAL;
  if (HAL_TIM_ConfigClockSource(&htim1, &sClockSourceConfig) != HAL_OK)
  {
    Error_Handler();
  }
  if (HAL_TIM_PWM_Init(&htim1) != HAL_OK)
  {
    Error_Handler();
  }
  if (HAL_TIM_OnePulse_Init(&htim1, TIM_OPMODE_SINGLE) != HAL_OK)
  {
    Error_Handler();
  }
  sMasterConfig.MasterOutputTrigger = TIM_TRGO_OC1REF;
  sMasterConfig.MasterSlaveMode = TIM_MASTERSLAVEMODE_DISABLE;
  if (HAL_TIMEx_MasterConfigSynchronization(&htim1, &sMasterConfig) != HAL_OK)
  {
    Error_Handler();
  }
  sConfigOC.OCMode = TIM_OCMODE_PWM1;
  sConfigOC.Pulse = 150;
  sConfigOC.OCPolarity = TIM_OCPOLARITY_HIGH;
  sConfigOC.OCNPolarity = TIM_OCNPOLARITY_HIGH;
  sConfigOC.OCFastMode = TIM_OCFAST_DISABLE;
  sConfigOC.OCIdleState = TIM_OCIDLESTATE_RESET;
  sConfigOC.OCNIdleState = TIM_OCNIDLESTATE_RESET;
  if (HAL_TIM_PWM_ConfigChannel(&htim1, &sConfigOC, TIM_CHANNEL_1) != HAL_OK)
  {
    Error_Handler();
  }
  sBreakDeadTimeConfig.OffStateRunMode = TIM_OSSR_DISABLE;
  sBreakDeadTimeConfig.OffStateIDLEMode = TIM_OSSI_DISABLE;
  sBreakDeadTimeConfig.LockLevel = TIM_LOCKLEVEL_OFF;
  sBreakDeadTimeConfig.DeadTime = 0;
  sBreakDeadTimeConfig.BreakState = TIM_BREAK_DISABLE;
  sBreakDeadTimeConfig.BreakPolarity = TIM_BREAKPOLARITY_HIGH;
  sBreakDeadTimeConfig.AutomaticOutput = TIM_AUTOMATICOUTPUT_DISABLE;
  if (HAL_TIMEx_ConfigBreakDeadTime(&htim1, &sBreakDeadTimeConfig) != HAL_OK)
  {
    Error_Handler();
  }

}

static void MX_TIM2_Init(void)
{

  TIM_ClockConfigTypeDef sClockSourceConfig = {0};
  TIM_SlaveConfigTypeDef sSlaveConfig = {0};
  TIM_MasterConfigTypeDef sMasterConfig = {0};
  TIM_OC_InitTypeDef sConfigOC = {0};

  htim2.Instance = TIM2;
  htim2.Init.Prescaler = 5-1;
  htim2.Init.CounterMode = TIM_COUNTERMODE_UP;
  htim2.Init.Period = 84-1;
  htim2.Init.ClockDivision = TIM_CLOCKDIVISION_DIV1;
  htim2.Init.AutoReloadPreload = TIM_AUTORELOAD_PRELOAD_DISABLE;
  if (HAL_TIM_Base_Init(&htim2) != HAL_OK)
  {
    Error_Handler();
  }
  sClockSourceConfig.ClockSource = TIM_CLOCKSOURCE_INTERNAL;
  if (HAL_TIM_ConfigClockSource(&htim2, &sClockSourceConfig) != HAL_OK)
  {
    Error_Handler();
  }
  if (HAL_TIM_PWM_Init(&htim2) != HAL_OK)
  {
    Error_Handler();
  }
  if (HAL_TIM_OnePulse_Init(&htim2, TIM_OPMODE_SINGLE) != HAL_OK)
  {
    Error_Handler();
  }
  sSlaveConfig.SlaveMode = TIM_SLAVEMODE_TRIGGER;
  sSlaveConfig.InputTrigger = TIM_TS_ITR0;
  if (HAL_TIM_SlaveConfigSynchro(&htim2, &sSlaveConfig) != HAL_OK)
  {
    Error_Handler();
  }
  sMasterConfig.MasterOutputTrigger = TIM_TRGO_RESET;
  sMasterConfig.MasterSlaveMode = TIM_MASTERSLAVEMODE_ENABLE;
  if (HAL_TIMEx_MasterConfigSynchronization(&htim2, &sMasterConfig) != HAL_OK)
  {
    Error_Handler();
  }
  sConfigOC.OCMode = TIM_OCMODE_PWM1;
  sConfigOC.Pulse = 75;
  sConfigOC.OCPolarity = TIM_OCPOLARITY_HIGH;
  sConfigOC.OCFastMode = TIM_OCFAST_DISABLE;
  if (HAL_TIM_PWM_ConfigChannel(&htim2, &sConfigOC, TIM_CHANNEL_1) != HAL_OK)
  {
    Error_Handler();
  }
  __HAL_TIM_DISABLE_OCxPRELOAD(&htim2, TIM_CHANNEL_1);
  if (HAL_TIM_PWM_ConfigChannel(&htim2, &sConfigOC, TIM_CHANNEL_2) != HAL_OK)
  {
    Error_Handler();
  }
  __HAL_TIM_DISABLE_OCxPRELOAD(&htim2, TIM_CHANNEL_2);
  HAL_TIM_MspPostInit(&htim2);

}

static void MX_TIM3_Init(void)
{

  TIM_ClockConfigTypeDef sClockSourceConfig = {0};
  TIM_SlaveConfigTypeDef sSlaveConfig = {0};
  TIM_MasterConfigTypeDef sMasterConfig = {0};
  TIM_OC_InitTypeDef sConfigOC = {0};

  htim3.Instance = TIM3;
  htim3.Init.Prescaler = 5-1;
  htim3.Init.CounterMode = TIM_COUNTERMODE_UP;
  htim3.Init.Period = 84-1;
  htim3.Init.ClockDivision = TIM_CLOCKDIVISION_DIV1;
  htim3.Init.AutoReloadPreload = TIM_AUTORELOAD_PRELOAD_DISABLE;
  if (HAL_TIM_Base_Init(&htim3) != HAL_OK)
  {
    Error_Handler();
  }
  sClockSourceConfig.ClockSource = TIM_CLOCKSOURCE_INTERNAL;
  if (HAL_TIM_ConfigClockSource(&htim3, &sClockSourceConfig) != HAL_OK)
  {
    Error_Handler();
  }
  if (HAL_TIM_PWM_Init(&htim3) != HAL_OK)
  {
    Error_Handler();
  }
  if (HAL_TIM_OnePulse_Init(&htim3, TIM_OPMODE_SINGLE) != HAL_OK)
  {
    Error_Handler();
  }
  sSlaveConfig.SlaveMode = TIM_SLAVEMODE_TRIGGER;
  sSlaveConfig.InputTrigger = TIM_TS_ITR0;
  if (HAL_TIM_SlaveConfigSynchro(&htim3, &sSlaveConfig) != HAL_OK)
  {
    Error_Handler();
  }
  sMasterConfig.MasterOutputTrigger = TIM_TRGO_RESET;
  sMasterConfig.MasterSlaveMode = TIM_MASTERSLAVEMODE_ENABLE;
  if (HAL_TIMEx_MasterConfigSynchronization(&htim3, &sMasterConfig) != HAL_OK)
  {
    Error_Handler();
  }
  sConfigOC.OCMode = TIM_OCMODE_PWM1;
  sConfigOC.Pulse = 75;
  sConfigOC.OCPolarity = TIM_OCPOLARITY_HIGH;
  sConfigOC.OCFastMode = TIM_OCFAST_DISABLE;
  if (HAL_TIM_PWM_ConfigChannel(&htim3, &sConfigOC, TIM_CHANNEL_1) != HAL_OK)
  {
    Error_Handler();
  }
  __HAL_TIM_DISABLE_OCxPRELOAD(&htim3, TIM_CHANNEL_1);
  if (HAL_TIM_PWM_ConfigChannel(&htim3, &sConfigOC, TIM_CHANNEL_4) != HAL_OK)
  {
    Error_Handler();
  }
  __HAL_TIM_DISABLE_OCxPRELOAD(&htim3, TIM_CHANNEL_4);
  HAL_TIM_MspPostInit(&htim3);

}

static void MX_TIM4_Init(void)
{

  TIM_ClockConfigTypeDef sClockSourceConfig = {0};
  TIM_SlaveConfigTypeDef sSlaveConfig = {0};
  TIM_MasterConfigTypeDef sMasterConfig = {0};
  TIM_OC_InitTypeDef sConfigOC = {0};

  htim4.Instance = TIM4;
  htim4.Init.Prescaler = 5-1;
  htim4.Init.CounterMode = TIM_COUNTERMODE_UP;
  htim4.Init.Period = 84-1;
  htim4.Init.ClockDivision = TIM_CLOCKDIVISION_DIV1;
  htim4.Init.AutoReloadPreload = TIM_AUTORELOAD_PRELOAD_DISABLE;
  if (HAL_TIM_Base_Init(&htim4) != HAL_OK)
  {
    Error_Handler();
  }
  sClockSourceConfig.ClockSource = TIM_CLOCKSOURCE_INTERNAL;
  if (HAL_TIM_ConfigClockSource(&htim4, &sClockSourceConfig) != HAL_OK)
  {
    Error_Handler();
  }
  if (HAL_TIM_PWM_Init(&htim4) != HAL_OK)
  {
    Error_Handler();
  }
  if (HAL_TIM_OnePulse_Init(&htim4, TIM_OPMODE_SINGLE) != HAL_OK)
  {
    Error_Handler();
  }
  sSlaveConfig.SlaveMode = TIM_SLAVEMODE_TRIGGER;
  sSlaveConfig.InputTrigger = TIM_TS_ITR0;
  if (HAL_TIM_SlaveConfigSynchro(&htim4, &sSlaveConfig) != HAL_OK)
  {
    Error_Handler();
  }
  sMasterConfig.MasterOutputTrigger = TIM_TRGO_RESET;
  sMasterConfig.MasterSlaveMode = TIM_MASTERSLAVEMODE_ENABLE;
  if (HAL_TIMEx_MasterConfigSynchronization(&htim4, &sMasterConfig) != HAL_OK)
  {
    Error_Handler();
  }
  sConfigOC.OCMode = TIM_OCMODE_PWM1;
  sConfigOC.Pulse = 75;
  sConfigOC.OCPolarity = TIM_OCPOLARITY_HIGH;
  sConfigOC.OCFastMode = TIM_OCFAST_DISABLE;
  if (HAL_TIM_PWM_ConfigChannel(&htim4, &sConfigOC, TIM_CHANNEL_2) != HAL_OK)
  {
    Error_Handler();
  }
  __HAL_TIM_DISABLE_OCxPRELOAD(&htim4, TIM_CHANNEL_2);
  HAL_TIM_MspPostInit(&htim4);

}

static void MX_TIM8_Init(void)
{

  TIM_ClockConfigTypeDef sClockSourceConfig = {0};
  TIM_SlaveConfigTypeDef sSlaveConfig = {0};
  TIM_MasterConfigTypeDef sMasterConfig = {0};
  TIM_OC_InitTypeDef sConfigOC = {0};
  TIM_BreakDeadTimeConfigTypeDef sBreakDeadTimeConfig = {0};

  htim8.Instance = TIM8;
  htim8.Init.Prescaler = 10-1;
  htim8.Init.CounterMode = TIM_COUNTERMODE_UP;
  htim8.Init.Period = 84-1;
  htim8.Init.ClockDivision = TIM_CLOCKDIVISION_DIV1;
  htim8.Init.RepetitionCounter = 0;
  htim8.Init.AutoReloadPreload = TIM_AUTORELOAD_PRELOAD_DISABLE;
  if (HAL_TIM_Base_Init(&htim8) != HAL_OK)
  {
    Error_Handler();
  }
  sClockSourceConfig.ClockSource = TIM_CLOCKSOURCE_INTERNAL;
  if (HAL_TIM_ConfigClockSource(&htim8, &sClockSourceConfig) != HAL_OK)
  {
    Error_Handler();
  }
  if (HAL_TIM_PWM_Init(&htim8) != HAL_OK)
  {
    Error_Handler();
  }
  if (HAL_TIM_OnePulse_Init(&htim8, TIM_OPMODE_SINGLE) != HAL_OK)
  {
    Error_Handler();
  }
  sSlaveConfig.SlaveMode = TIM_SLAVEMODE_TRIGGER;
  sSlaveConfig.InputTrigger = TIM_TS_ITR0;
  if (HAL_TIM_SlaveConfigSynchro(&htim8, &sSlaveConfig) != HAL_OK)
  {
    Error_Handler();
  }
  sMasterConfig.MasterOutputTrigger = TIM_TRGO_RESET;
  sMasterConfig.MasterSlaveMode = TIM_MASTERSLAVEMODE_ENABLE;
  if (HAL_TIMEx_MasterConfigSynchronization(&htim8, &sMasterConfig) != HAL_OK)
  {
    Error_Handler();
  }
  sConfigOC.OCMode = TIM_OCMODE_PWM1;
  sConfigOC.Pulse = 70;
  sConfigOC.OCPolarity = TIM_OCPOLARITY_HIGH;
  sConfigOC.OCNPolarity = TIM_OCNPOLARITY_HIGH;
  sConfigOC.OCFastMode = TIM_OCFAST_DISABLE;
  sConfigOC.OCIdleState = TIM_OCIDLESTATE_RESET;
  sConfigOC.OCNIdleState = TIM_OCNIDLESTATE_RESET;
  if (HAL_TIM_PWM_ConfigChannel(&htim8, &sConfigOC, TIM_CHANNEL_2) != HAL_OK)
  {
    Error_Handler();
  }
  __HAL_TIM_DISABLE_OCxPRELOAD(&htim8, TIM_CHANNEL_2);
  sBreakDeadTimeConfig.OffStateRunMode = TIM_OSSR_DISABLE;
  sBreakDeadTimeConfig.OffStateIDLEMode = TIM_OSSI_DISABLE;
  sBreakDeadTimeConfig.LockLevel = TIM_LOCKLEVEL_OFF;
  sBreakDeadTimeConfig.DeadTime = 0;
  sBreakDeadTimeConfig.BreakState = TIM_BREAK_DISABLE;
  sBreakDeadTimeConfig.BreakPolarity = TIM_BREAKPOLARITY_HIGH;
  sBreakDeadTimeConfig.AutomaticOutput = TIM_AUTOMATICOUTPUT_DISABLE;
  if (HAL_TIMEx_ConfigBreakDeadTime(&htim8, &sBreakDeadTimeConfig) != HAL_OK)
  {
    Error_Handler();
  }
  HAL_TIM_MspPostInit(&htim8);

}

static void MX_USART2_UART_Init(void)
{

  huart2.Instance = USART2;
  huart2.Init.BaudRate = 38400;
  huart2.Init.WordLength = UART_WORDLENGTH_8B;
  huart2.Init.StopBits = UART_STOPBITS_1;
  huart2.Init.Parity = UART_PARITY_NONE;
  huart2.Init.Mode = UART_MODE_TX_RX;
  huart2.Init.HwFlowCtl = UART_HWCONTROL_NONE;
  huart2.Init.OverSampling = UART_OVERSAMPLING_16;
  if (HAL_UART_Init(&huart2) != HAL_OK)
  {
    Error_Handler();
  }

}

static void MX_DMA_Init(void)
{

  /* DMA controller clock enable */
  __HAL_RCC_DMA1_CLK_ENABLE();
  __HAL_RCC_DMA2_CLK_ENABLE();

  /* DMA interrupt init */
  /* DMA1_Stream2_IRQn interrupt configuration */
  HAL_NVIC_SetPriority(DMA1_Stream2_IRQn, 5, 0);
  HAL_NVIC_EnableIRQ(DMA1_Stream2_IRQn);
  /* DMA1_Stream4_IRQn interrupt configuration */
  HAL_NVIC_SetPriority(DMA1_Stream4_IRQn, 5, 0);
  HAL_NVIC_EnableIRQ(DMA1_Stream4_IRQn);
  /* DMA1_Stream5_IRQn interrupt configuration */
  HAL_NVIC_SetPriority(DMA1_Stream5_IRQn, 5, 0);
  HAL_NVIC_EnableIRQ(DMA1_Stream5_IRQn);
  /* DMA1_Stream6_IRQn interrupt configuration */
  HAL_NVIC_SetPriority(DMA1_Stream6_IRQn, 5, 0);
  HAL_NVIC_EnableIRQ(DMA1_Stream6_IRQn);
  /* DMA1_Stream7_IRQn interrupt configuration */
  HAL_NVIC_SetPriority(DMA1_Stream7_IRQn, 5, 0);
  HAL_NVIC_EnableIRQ(DMA1_Stream7_IRQn);
  /* DMA2_Stream0_IRQn interrupt configuration */
  HAL_NVIC_SetPriority(DMA2_Stream0_IRQn, 5, 0);
  HAL_NVIC_EnableIRQ(DMA2_Stream0_IRQn);

}

static void MX_GPIO_Init(void)
{
  GPIO_InitTypeDef GPIO_InitStruct = {0};

  /* GPIO Ports Clock Enable */
  __HAL_RCC_GPIOC_CLK_ENABLE();
  __HAL_RCC_GPIOH_CLK_ENABLE();
  __HAL_RCC_GPIOA_CLK_ENABLE();
  __HAL_RCC_GPIOB_CLK_ENABLE();
  __HAL_RCC_GPIOD_CLK_ENABLE();

  /*Configure GPIO pin Output Level */
  HAL_GPIO_WritePin(GPIOC, LAT2_Pin|SIN2_Pin|VOUT1_EN_Pin, GPIO_PIN_RESET);

  /*Configure GPIO pin Output Level */
  HAL_GPIO_WritePin(GPIOC, BLK2_Pin|BLK12_Pin|BLK8_Pin, GPIO_PIN_SET);

  /*Configure GPIO pin Output Level */
  HAL_GPIO_WritePin(GPIOA, RST_Pin|LAT12_Pin|SIN12_Pin|WC_Pin, GPIO_PIN_RESET);

  /*Configure GPIO pin Output Level */
  HAL_GPIO_WritePin(GPIOB, LAT10_Pin|SIN10_Pin|LAT8_Pin|SIN8_Pin
                          |SIN6_Pin|LAT4_Pin|SIN4_Pin, GPIO_PIN_RESET);

  /*Configure GPIO pin Output Level */
  HAL_GPIO_WritePin(GPIOB, BLK10_Pin|BLK6_Pin|BLK4_Pin, GPIO_PIN_SET);

  /*Configure GPIO pin Output Level */
  HAL_GPIO_WritePin(LAT6_GPIO_Port, LAT6_Pin, GPIO_PIN_RESET);

  /*Configure GPIO pins : PC13 PC0 PC8 */
  GPIO_InitStruct.Pin = GPIO_PIN_13|GPIO_PIN_0|GPIO_PIN_8;
  GPIO_InitStruct.Mode = GPIO_MODE_ANALOG;
  GPIO_InitStruct.Pull = GPIO_NOPULL;
  HAL_GPIO_Init(GPIOC, &GPIO_InitStruct);

  /*Configure GPIO pins : LAT2_Pin SIN2_Pin BLK2_Pin BLK12_Pin
                           BLK8_Pin VOUT1_EN_Pin */
  GPIO_InitStruct.Pin = LAT2_Pin|SIN2_Pin|BLK2_Pin|BLK12_Pin
                          |BLK8_Pin|VOUT1_EN_Pin;
  GPIO_InitStruct.Mode = GPIO_MODE_OUTPUT_PP;
  GPIO_InitStruct.Pull = GPIO_NOPULL;
  GPIO_InitStruct.Speed = GPIO_SPEED_FREQ_LOW;
  HAL_GPIO_Init(GPIOC, &GPIO_InitStruct);

  /*Configure GPIO pins : RST_Pin LAT12_Pin SIN12_Pin WC_Pin */
  GPIO_InitStruct.Pin = RST_Pin|LAT12_Pin|SIN12_Pin|WC_Pin;
  GPIO_InitStruct.Mode = GPIO_MODE_OUTPUT_PP;
  GPIO_InitStruct.Pull = GPIO_NOPULL;
  GPIO_InitStruct.Speed = GPIO_SPEED_FREQ_LOW;
  HAL_GPIO_Init(GPIOA, &GPIO_InitStruct);

  /*Configure GPIO pin : IO0_Pin */
  GPIO_InitStruct.Pin = IO0_Pin;
  GPIO_InitStruct.Mode = GPIO_MODE_IT_RISING_FALLING;
  GPIO_InitStruct.Pull = GPIO_NOPULL;
  HAL_GPIO_Init(IO0_GPIO_Port, &GPIO_InitStruct);

  /*Configure GPIO pins : LAT10_Pin SIN10_Pin BLK10_Pin LAT8_Pin
                           SIN8_Pin SIN6_Pin BLK6_Pin LAT4_Pin
                           SIN4_Pin BLK4_Pin */
  GPIO_InitStruct.Pin = LAT10_Pin|SIN10_Pin|BLK10_Pin|LAT8_Pin
                          |SIN8_Pin|SIN6_Pin|BLK6_Pin|LAT4_Pin
                          |SIN4_Pin|BLK4_Pin;
  GPIO_InitStruct.Mode = GPIO_MODE_OUTPUT_PP;
  GPIO_InitStruct.Pull = GPIO_NOPULL;
  GPIO_InitStruct.Speed = GPIO_SPEED_FREQ_LOW;
  HAL_GPIO_Init(GPIOB, &GPIO_InitStruct);

  /*Configure GPIO pins : PB2 PB12 */
  GPIO_InitStruct.Pin = GPIO_PIN_2|GPIO_PIN_12;
  GPIO_InitStruct.Mode = GPIO_MODE_ANALOG;
  GPIO_InitStruct.Pull = GPIO_NOPULL;
  HAL_GPIO_Init(GPIOB, &GPIO_InitStruct);

  /*Configure GPIO pin : FAULT_Pin */
  GPIO_InitStruct.Pin = FAULT_Pin;
  GPIO_InitStruct.Mode = GPIO_MODE_INPUT;
  GPIO_InitStruct.Pull = GPIO_NOPULL;
  HAL_GPIO_Init(FAULT_GPIO_Port, &GPIO_InitStruct);

  /*Configure GPIO pins : PA10 PA15 */
  GPIO_InitStruct.Pin = GPIO_PIN_10|GPIO_PIN_15;
  GPIO_InitStruct.Mode = GPIO_MODE_ANALOG;
  GPIO_InitStruct.Pull = GPIO_NOPULL;
  HAL_GPIO_Init(GPIOA, &GPIO_InitStruct);

  /*Configure GPIO pin : LAT6_Pin */
  GPIO_InitStruct.Pin = LAT6_Pin;
  GPIO_InitStruct.Mode = GPIO_MODE_OUTPUT_PP;
  GPIO_InitStruct.Pull = GPIO_NOPULL;
  GPIO_InitStruct.Speed = GPIO_SPEED_FREQ_LOW;
  HAL_GPIO_Init(LAT6_GPIO_Port, &GPIO_InitStruct);

  /* EXTI interrupt init*/
  HAL_NVIC_SetPriority(EXTI4_IRQn, 5, 0);
  HAL_NVIC_EnableIRQ(EXTI4_IRQn);

}

/* USER CODE BEGIN 4 */
void HAL_TIM_PWM_PulseFinishedCallback(TIM_HandleTypeDef *htim)
{
	if (htim == &htim1)
	{
		static uint16_t newarr_inc = 0x8000U;

		HAL_GPIO_WritePin(SIN12_GPIO_Port, SIN12_Pin,( ((newarr[0] & newarr_inc) != 0)  ? GPIO_PIN_SET : GPIO_PIN_RESET) );
		HAL_GPIO_WritePin(SIN2_GPIO_Port, SIN2_Pin,( ((newarr[1] & newarr_inc) != 0)  ? GPIO_PIN_SET : GPIO_PIN_RESET) );
		HAL_GPIO_WritePin(SIN4_GPIO_Port, SIN4_Pin,( ((newarr[2] & newarr_inc) != 0)  ? GPIO_PIN_SET : GPIO_PIN_RESET) );
		HAL_GPIO_WritePin(SIN6_GPIO_Port, SIN6_Pin,( ((newarr[3] & newarr_inc) != 0)  ? GPIO_PIN_SET : GPIO_PIN_RESET) );
		HAL_GPIO_WritePin(SIN8_GPIO_Port, SIN8_Pin,( ((newarr[4] & newarr_inc) != 0)  ? GPIO_PIN_SET : GPIO_PIN_RESET) );
		HAL_GPIO_WritePin(SIN10_GPIO_Port, SIN10_Pin,( ((newarr[5] & newarr_inc) != 0)  ? GPIO_PIN_SET : GPIO_PIN_RESET) );

		if (newarr_inc != 0x0001U)
			newarr_inc >>= 1;
		else
		{
			newarr_inc = 0x8000U;
			osThreadFlagsSet(TimerAndLatchHandle, LATMASK);
		}

	}
}

void HAL_RTC_AlarmAEventCallback(RTC_HandleTypeDef *hrtc)
{
	HAL_RNG_GenerateRandomNumber_IT(&hrng);
//	osEventFlagsSet(GlobalStatusHandle, 0x00010101U); // set minute flags for all threads
//	osThreadFlagsSet(RGBShiftHandle, MINMASK);
	osThreadFlagsSet(ClockManageHandle, MINMASK);
//	osThreadFlagsSet(RTCManageHandle, MINMASK);
}

void HAL_GPIO_EXTI_Callback(uint16_t GPIO_Pin)
{
	if(GPIO_Pin == IO0_Pin)
	{
		if(HAL_GPIO_ReadPin(IO0_GPIO_Port, IO0_Pin) == 0)
		{
			txbuff[0] = 0x55;
//			HAL_UART_DMAResume(&huart2);
			wififlag = wififlag | WIFISTATUS;
			HAL_UART_Receive_DMA(&huart2, rxbuff, 6);
			HAL_UART_Transmit_DMA(&huart2, txbuff, 1);
			osThreadFlagsSet(ClockManageHandle, WIFISTATUS);
		}
		else
		{
			wififlag = wififlag & ~WIFISTATUS;
			HAL_UART_Abort(&huart2);
			osThreadFlagsSet(ClockManageHandle, WIFISTATUSD);
		}
	}
}

void HAL_UART_RxCpltCallback(UART_HandleTypeDef *huart)
{
	if (huart->Instance == huart2.Instance)
	{
		wififlag = wififlag | ESPDATA;
		osThreadFlagsSet(ClockManageHandle, ESPDATA);
//		osThreadFlagsSet(ClockManageHandle, ESPDATA);
	}
}

/* USER CODE END 4 */

void startTimerAndLatch(void *argument)
{
  /* init code for USB_DEVICE */
  MX_USB_DEVICE_Init();
  /* USER CODE BEGIN 5 */
  HAL_GPIO_WritePin(BLK2_GPIO_Port, BLK2_Pin, GPIO_PIN_RESET);
  HAL_GPIO_WritePin(BLK4_GPIO_Port, BLK4_Pin, GPIO_PIN_RESET);
  HAL_GPIO_WritePin(BLK6_GPIO_Port, BLK6_Pin, GPIO_PIN_RESET);
  HAL_GPIO_WritePin(BLK8_GPIO_Port, BLK8_Pin, GPIO_PIN_RESET);
  HAL_GPIO_WritePin(BLK10_GPIO_Port, BLK10_Pin, GPIO_PIN_RESET);
  HAL_GPIO_WritePin(BLK12_GPIO_Port, BLK12_Pin, GPIO_PIN_RESET);

  /* Infinite loop */
  for(;;)
  {
	  osThreadFlagsWait(TIMMASK, osFlagsWaitAny, osWaitForever);

	  TIM1->CR1 |= TIM_CR1_CEN;
	  HAL_TIM_PWM_Start_IT(&htim1, TIM_CHANNEL_2);
	  osThreadFlagsWait(LATMASK, osFlagsWaitAny, osWaitForever);

	  HAL_GPIO_WritePin(LAT2_GPIO_Port, LAT2_Pin, GPIO_PIN_SET);
	  HAL_GPIO_WritePin(LAT4_GPIO_Port, LAT4_Pin, GPIO_PIN_SET);
	  HAL_GPIO_WritePin(LAT6_GPIO_Port, LAT6_Pin, GPIO_PIN_SET);
	  HAL_GPIO_WritePin(LAT8_GPIO_Port, LAT8_Pin, GPIO_PIN_SET);
	  HAL_GPIO_WritePin(LAT10_GPIO_Port, LAT10_Pin, GPIO_PIN_SET);
	  HAL_GPIO_WritePin(LAT12_GPIO_Port, LAT12_Pin, GPIO_PIN_SET);
	  HAL_GPIO_WritePin(LAT2_GPIO_Port, LAT2_Pin, GPIO_PIN_RESET);
	  HAL_GPIO_WritePin(LAT4_GPIO_Port, LAT4_Pin, GPIO_PIN_RESET);
	  HAL_GPIO_WritePin(LAT6_GPIO_Port, LAT6_Pin, GPIO_PIN_RESET);
	  HAL_GPIO_WritePin(LAT8_GPIO_Port, LAT8_Pin, GPIO_PIN_RESET);
	  HAL_GPIO_WritePin(LAT10_GPIO_Port, LAT10_Pin, GPIO_PIN_RESET);
	  HAL_GPIO_WritePin(LAT12_GPIO_Port, LAT12_Pin, GPIO_PIN_RESET);

  }
  /* USER CODE END 5 */
}

void StartLEDShift(void *argument)
{
  /* USER CODE BEGIN StartLEDShift */
  /* Infinite loop */
  for(;;)
  {
	  osDelay(10000);
  }

  /* USER CODE END StartLEDShift */
}

/* USER CODE BEGIN Header_StartRGBShift */
/**
* @brief Function implementing the RGBShift thread.
* @param argument: Not used
* @retval N one
*/
/* USER CODE END Header_StartRGBShift */
void StartRGBShift(void *argument)
{
  /* USER CODE BEGIN StartRGBShift */
//	uint8_t i = 0;
//	RTC_TimeTypeDef sTime = {0};
//	RTC_DateTypeDef sDate = {0};

	uint8_t parr[NUMPIXELS][PIXELARR];
	fillColor(parr, Blue);
	uint8_t farr[NUMPIXELS][PIXELARR];
	fillColor(farr, White);
	uint8_t carr[NUMPIXELS + 2][PIXELARR + 1];
	int index = 0;

	HAL_RNG_GenerateRandomNumber_IT(&hrng);

	HAL_GPIO_WritePin(VOUT1_EN_GPIO_Port, VOUT1_EN_Pin, GPIO_PIN_SET); // Vout1 en

	uint32_t tick = osKernelGetTickCount();
	uint32_t rng = 0;

  /* Infinite loop */
  for(;;)
  {
	  tick += 20;
	  rng = HAL_RNG_ReadLastRandomNumber(&hrng);
//	  filterPointReset(farr, index);
	  fadeToBlackBy(farr, (uint8_t *) index, FFSHORT, 10, rng, 0x07);
//	  filterPointReset(farr, index);
	  pointfill(parr, farr, Gray, index);
	  index = (index + 1 ) % 60;
	  composite(carr, parr, farr, 37, -23, 0xE7);

//	  HAL_SPI_Transmit(&hspi3, (uint8_t *) &carr, sizeof(carr), HAL_MAX_DELAY);
	  HAL_SPI_Transmit_DMA(&hspi3, (uint8_t *) &carr, sizeof(carr));
	  HAL_RNG_GenerateRandomNumber_IT(&hrng);
	  osDelayUntil(tick);

  }
  /* USER CODE END StartRGBShift */
}

void StartRTCManage(void *argument)
{
  /* USER CODE BEGIN StartRTCManage */
	RTC_TimeTypeDef sTime = {0};
	RTC_DateTypeDef sDate = {0};
	uint8_t posm = 0;
	uint8_t posh = 0;
	uint16_t x[6];
	uint32_t temp[] = {0, 0, 0};
	uint32_t temp1[] = {0, 0, 0};
	uint32_t mflags[2] = {0x00};
	uint16_t hflags = 0x00;
  /* Infinite loop */
  for(;;)
  {
	  //values for time s hould be passed to this thread
//	  osThreadFlagsWait(0x01, osFlagsWaitAny, 0x03FFU);
	  HAL_RTC_GetTime(&hrtc, &sTime, RTC_FORMAT_BIN);
	  HAL_RTC_GetDate(&hrtc, &sDate, RTC_FORMAT_BIN);

	  if ((sTime.Minutes == 0 ) && (sTime.Seconds <= 5))
	  {
		  int mod = 0;
		  int div = 0;
		  int moda = 0;
		  int diva = 0;
		  mflags[0] = 0;
		  mflags[1] = 0;
		  for(int i = 0; i<30; i++)
		  {
			  mod = (2 * i + 0) % 30;
			  div = (2 * i + 0) / 30;
			  moda = (59 - (2 * i ) ) % 30;
			  diva = (59 - (2 * i ) ) / 30;

			  mflags[div] |= (0x01<<mod);
			  mflags[diva] |= (0x01 << moda);

			  if (i % 2 == 0)
			  {
				  hflags >>= 1;
				  hflags |= 0x01<<12;
			  }
			  else
			  {
				  hflags >>=1;
			  }
			  displayData(newarr, mflags, hflags);
			  osThreadFlagsSet(TimerAndLatchHandle, TIMMASK);
			  osDelay(100);f
		  }
		  for (int i = 0; i < 30; i++)
		  {
			  mflags[0] &= ~(1<<(29 - i));
			  mflags[1]  &= ~(1<<i);
			  if (i % 2 == 0)
			  {
				  hflags >>= 1;
				  hflags |= 0x01<<12;
			  }
			  else
				  hflags >>=1;

			  displayData(newarr, mflags, hflags);
			  osThreadFlagsSet(TimerAndLatchHandle, TIMMASK);
			  osDelay(100);
		  }

	  }
	  hflags = 0x00;
	  mflags[0] = 0;
	  mflags[1] = 0;
//	  for(int i = 0; i < 24; i++)
//	  {
//		   if((hflags & 0x1000)!= 0)
//			  hflags = (hflags & 0xFFF)|0x01;
//		  displayData(newarr, mflags, hflags);
//		  hflags <<=1;
//		  osThreadFlagsSet(TimerAndLatchHandle, TIMMASK);
//		  osDelay(200);
//	  }

	  int d =((min)% 60);
	  mflags[d / 30] = 0x01 << (d% 30);
	  hflags = 0x01 << ((hrs) % 12);
	  displayData(newarr, mflags, hflags);

	  osThreadFlagsSet(TimerAndLatchHandle, TIMMASK);
	  osThreadFlagsWait(MINMASK, osFlagsWaitAny, osWaitForever);
  }
  /* USER CODE END StartRTCManage */
}

void StartClockMngr(void *argument)
{
  /* USER CODE BEGIN StartClockMngr */
	HAL_GPIO_WritePin(RST_GPIO_Port, RST_Pin, GPIO_PIN_SET);
	RTC_TimeTypeDef sTime = {0};
	RTC_DateTypeDef sDate = {0};
	uint32_t flags = 0;
	int updateflag = 0;
	uint32_t makeTime = 0x00;
	tm rawTime;
//	uint8_t rxBuff[] = {0x00, 0x00,0x00,0x00,0x00};

	HAL_GPIO_WritePin(RST_GPIO_Port, RST_Pin, GPIO_PIN_SET);
  /* Infinite loop */
  for(;;)
  {

	  HAL_RTC_GetTime(&hrtc, &sTime, RTC_FORMAT_BIN);
	  HAL_RTC_GetDate(&hrtc, &sDate, RTC_FORMAT_BIN);

	  if (HAL_GPIO_ReadPin(IO0_GPIO_Port, IO0_Pin) == 0)
//		  flags = 1;
//	  else
//		  flags = 0;
//	  if ( (wififlag & (WIFISTATUS )) == (WIFISTATUS ))
	  {// Check if we got 0x5
//		  HAL_UART_Receive_DMA(&huart2, rxbuff, 6);
//		  HAL_UART_Transmit_DMA(&huart2, txbuff, 1);

		  osThreadFlagsWait(ESPDATA, osFlagsWaitAny, 100);

		  //Clear data callback flag
		  osEventFlagsClear(GlobalStatusHandle, ESPDATA);
		  if (rxbuff[0] == 0x55)
		  {
			  //Set rxbuff to zero
			  rxbuff[0] = 0x00;
			  makeTime = ((rxbuff[1]<<24) + (rxbuff[2]<<16) + (rxbuff[3]<<8) + (rxbuff[4]));
			  rawTime = breaktime(makeTime);
			  sTime.Hours = rawTime.hour;
			  sTime.Minutes = rawTime.minute;
			  sTime.Seconds = rawTime.second;
			  sTime.TimeFormat = RTC_HOURFORMAT12_AM;
			  sTime.DayLightSaving = RTC_DAYLIGHTSAVING_NONE;
			  sTime.StoreOperation = RTC_STOREOPERATION_RESET;
			  sDate.Date = rawTime.day;
			  sDate.Month = rawTime.month;
			  sDate.Year = rawTime.year;
			  sDate.WeekDay = (rawTime.weekday == 0x00 ? 0x07 : rawTime.weekday);
			  HAL_RTC_SetTime(&hrtc, &sTime, RTC_FORMAT_BIN);
			  HAL_RTC_SetDate(&hrtc, &sDate, RTC_FORMAT_BIN);
			  osThreadFlagsSet(RTCManageHandle, MINMASK);
			  updateflag = 1;
			  rxbuff[6] = '\r';
			  rxbuff[7] = '\n';
			  CDC_Transmit_FS(rxbuff, 8);
//			  osThreadYield();
		  }
//		  if(rxbuff[0] != 0x00)
//		  {
//			  HAL_UART_Receive_DMA(&huart2, rxbuff, 6);
//			  HAL_UART_Transmit_DMA(&huart2, txbuff, 1);
//		  }

	  }
	  osThreadFlagsSet(RGBShiftHandle, MINMASK);
	  osThreadFlagsSet(RTCManageHandle, MINMASK);
	  osThreadFlagsWait(MINMASK, osFlagsWaitAny, 2000);
	  HAL_RTC_GetTime(&hrtc, &sTime, RTC_FORMAT_BIN);
	  HAL_RTC_GetDate(&hrtc, &sDate, RTC_FORMAT_BIN);
	  min = sTime.Minutes;
	  hrs = sTime.Hours;
	  CDC_Transmit_FS(rxbuff, 8);

	  if ((sTime.Minutes % 5 == 0) && (sTime.Seconds >= 50) && (rxbuff[0] == 0x00))
	  {
		  if (updateflag)
		  {
			  HAL_UART_Abort(&huart2);
			  HAL_UART_DMAResume(&huart2);
			  HAL_UART_Receive_DMA(&huart2, rxbuff, 6);
			  HAL_UART_Transmit_DMA(&huart2, txbuff, 1);
			  updateflag = 0;

		  }
	  }

  }
  /* USER CODE END StartClockMngr */
}

 /**
  * @brief  Period elapsed callback in non blocking mode
  * @note   This function is called  when TIM7 interrupt took place, inside
  * HAL_TIM_IRQHandler(). It makes a direct call to HAL_IncTick() to increment
  * a global variable "uwTick" used as application time base.
  * @param  htim : TIM handle
  * @retval None
  */
void HAL_TIM_PeriodElapsedCallback(TIM_HandleTypeDef *htim)
{
  if (htim->Instance == TIM7) {
    HAL_IncTick();
  }
}

void Error_Handler(void)
{
  __disable_irq();
  while (1)
  {
  }
}

/************************ (C) COPYRIGHT STMicroelectronics *****END OF FILE****/
